# CY8C4A45LQI_483 register map
File version: 0.1
PSoC Analog Coprocessor
Registers are 32-bit, read-write, no defined reset value unless marked. A register's access mark holds for its fields unless they carry their own. Offsets are from the block's base; lines under a group give offsets from that group; [hi:lo] are bit positions; {n}, {i} and the like mark numbered series; 'fields as' and 'values as' point back to an identical list; <NAME> marks a mode.

## Memory map
0x00000000 Opamp_1 — OpAmp
0x00000000 Timebase5s
0x00000000 CSD
0x00000000 PIRAmplifierStage1 — OpAmp
0x00000000 RefBuffer — OpAmp
0x00000000 ADC
0x00000000 PIRAmplifierStage2 — PGA
0x00000000 EzI2C — Serial Communication Block
0x40000000 DMAC — DMAC Registers

## Opamp_1 — OpAmp
Base 0x00000000
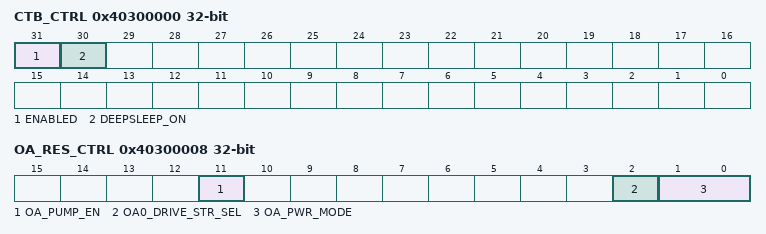
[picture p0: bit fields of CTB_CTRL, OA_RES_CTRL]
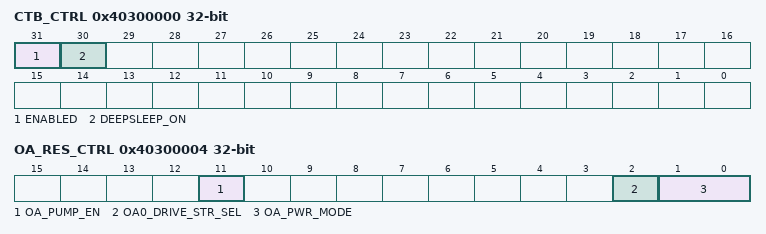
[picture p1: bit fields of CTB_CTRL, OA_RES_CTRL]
0x40300000 CTB_CTRL — Global CTB IP and power control
  [31] ENABLED — Selects component behavior in DeepSleep power mode
    0=DISABLE (CTB IP disabled (put analog in power down, open all switches)); 1=ENABLE (CTB IP enabledCTB IP enabled)
  [30] DEEPSLEEP_ON — Selects component behavior in DeepSleep power mode
    0=DISABLE (CTB IP disabled off during DeepSleep power mode); 1=ENABLE (CTB IP remains enabled during DeepSleep power mode (if ENABLED=1))
0x40300008 OA_RES_CTRL — Opamp and resistor control
  [11] OA_PUMP_EN — Selects pump
    0=DISABLE (Pump disabled); 1=ENABLE (Pump enabled)
  [2] OA0_DRIVE_STR_SEL — Opamp output strenght select
    0=Cy1x (Internal only); 1=Cy10x (Output to pin)
  [1:0] OA_PWR_MODE — Selects power for opamp
    0=OFF; 1=LOW (Low power); 2=MED (Medium power); 3=HIGH (High power)
0x40300F14 OA_COMP_TRIM — Opamp Compenation Capacitor Trim
  [1:0] OA_COMP_TRIM
    1=HIGH_SPEED; 2=BALANCED; 3=HIGH_STABILITY

## Timebase5s
Base 0x00000000
0x40010108 COUNTER — Current counter value
0x4001010C CC — Compare / capture value
0x40010110 CC_BUF — Compare / capture buffer value
0x40010114 PERIOD — Period value
0x40010118 PERIOD_BUF — Period buffer value

## PIRAmplifierStage1 — OpAmp
Base 0x00000000
0x40300000 CTB_CTRL — Global CTB IP and power control
  [31] ENABLED — Selects component behavior in DeepSleep power mode
    0=DISABLE (CTB IP disabled (put analog in power down, open all switches)); 1=ENABLE (CTB IP enabledCTB IP enabled)
  [30] DEEPSLEEP_ON — Selects component behavior in DeepSleep power mode
    0=DISABLE (CTB IP disabled off during DeepSleep power mode); 1=ENABLE (CTB IP remains enabled during DeepSleep power mode (if ENABLED=1))
0x40300004 OA_RES_CTRL — Opamp and resistor control
  [11] OA_PUMP_EN — Selects pump
    0=DISABLE (Pump disabled); 1=ENABLE (Pump enabled)
  [2] OA0_DRIVE_STR_SEL — Opamp output strenght select
    0=Cy1x (Internal only); 1=Cy10x (Output to pin)
  [1:0] OA_PWR_MODE — Selects power for opamp
    0=OFF; 1=LOW (Low power); 2=MED (Medium power); 3=HIGH (High power)
0x40300F08 OA_COMP_TRIM — Opamp Compenation Capacitor Trim
  [1:0] OA_COMP_TRIM
    1=HIGH_SPEED; 2=BALANCED; 3=HIGH_STABILITY

## RefBuffer — OpAmp
Base 0x00000000
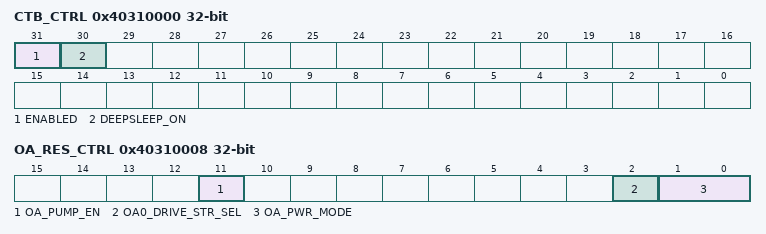
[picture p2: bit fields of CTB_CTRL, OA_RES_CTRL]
0x40310000 CTB_CTRL — Global CTB IP and power control
  [31] ENABLED — Selects component behavior in DeepSleep power mode
    0=DISABLE (CTB IP disabled (put analog in power down, open all switches)); 1=ENABLE (CTB IP enabledCTB IP enabled)
  [30] DEEPSLEEP_ON — Selects component behavior in DeepSleep power mode
    0=DISABLE (CTB IP disabled off during DeepSleep power mode); 1=ENABLE (CTB IP remains enabled during DeepSleep power mode (if ENABLED=1))
0x40310008 OA_RES_CTRL — Opamp and resistor control
  [11] OA_PUMP_EN — Selects pump
    0=DISABLE (Pump disabled); 1=ENABLE (Pump enabled)
  [2] OA0_DRIVE_STR_SEL — Opamp output strenght select
    0=Cy1x (Internal only); 1=Cy10x (Output to pin)
  [1:0] OA_PWR_MODE — Selects power for opamp
    0=OFF; 1=LOW (Low power); 2=MED (Medium power); 3=HIGH (High power)
0x40310F14 OA_COMP_TRIM — Opamp Compenation Capacitor Trim
  [1:0] OA_COMP_TRIM
    1=HIGH_SPEED; 2=BALANCED; 3=HIGH_STABILITY
